# STM32L011K4U7 register map
File version: 1.0
Registers are 32-bit, access not given, reset 0x0 unless marked. A register's access mark holds for its fields unless they carry their own. Offsets are from the block's base; [hi:lo] are bit positions; {n}, {i} and the like mark numbered series.

## IWDG
Base 0x40003000
0x00 KR
  [15:0] KEY
0x04 PR
  [2:0] PR
0x08 RLR
  [11:0] RL
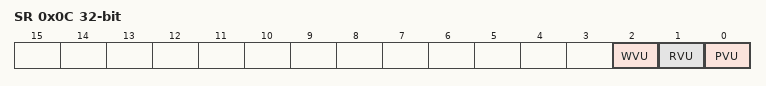
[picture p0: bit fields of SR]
0x0C SR
  [2] WVU, [1] RVU, [0] PVU
0x10 WINR
  [11:0] WIN

## USART2
Base 0x40004400
Same registers: LPUART1 0x40004800
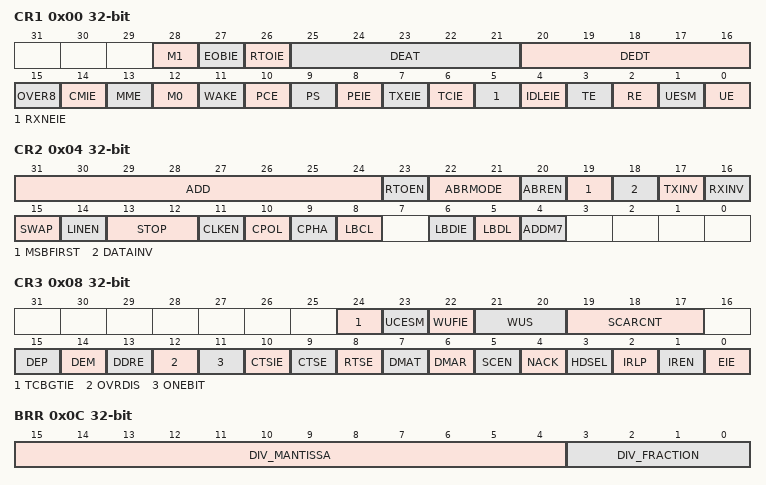
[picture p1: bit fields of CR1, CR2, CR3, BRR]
0x00 CR1
  [28] M1, [27] EOBIE, [26] RTOIE, [25:21] DEAT, [20:16] DEDT, [15] OVER8, [14] CMIE, [13] MME, [12] M0, [11] WAKE, [10] PCE, [9] PS, [8] PEIE, [7] TXEIE, [6] TCIE, [5] RXNEIE, [4] IDLEIE, [3] TE, [2] RE, [1] UESM, [0] UE
0x04 CR2
  [31:24] ADD, [23] RTOEN, [22:21] ABRMODE, [20] ABREN, [19] MSBFIRST, [18] DATAINV, [17] TXINV, [16] RXINV, [15] SWAP, [14] LINEN, [13:12] STOP, [11] CLKEN, [10] CPOL, [9] CPHA, [8] LBCL, [6] LBDIE, [5] LBDL, [4] ADDM7
0x08 CR3
  [24] TCBGTIE, [23] UCESM, [22] WUFIE, [21:20] WUS, [19:17] SCARCNT, [15] DEP, [14] DEM, [13] DDRE, [12] OVRDIS, [11] ONEBIT, [10] CTSIE, [9] CTSE, [8] RTSE, [7] DMAT, [6] DMAR, [5] SCEN, [4] NACK, [3] HDSEL, [2] IRLP, [1] IREN, [0] EIE
0x0C BRR
  [15:4] DIV_MANTISSA, [3:0] DIV_FRACTION
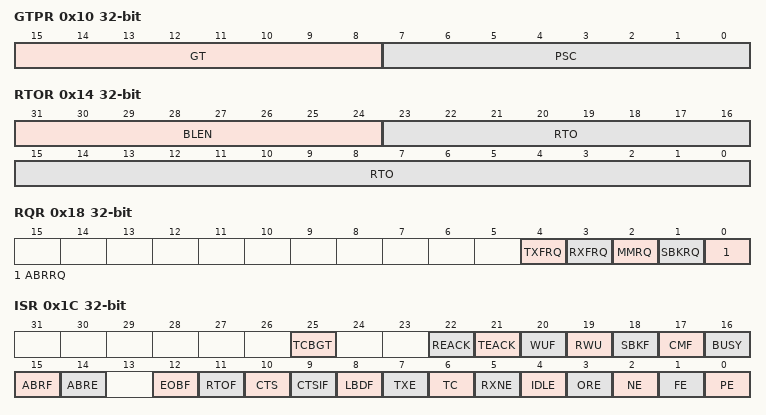
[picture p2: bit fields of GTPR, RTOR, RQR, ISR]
0x10 GTPR
  [15:8] GT, [7:0] PSC
0x14 RTOR
  [31:24] BLEN, [23:0] RTO
0x18 RQR
  [4] TXFRQ, [3] RXFRQ, [2] MMRQ, [1] SBKRQ, [0] ABRRQ
0x1C ISR
  [25] TCBGT, [22] REACK, [21] TEACK, [20] WUF, [19] RWU, [18] SBKF, [17] CMF, [16] BUSY, [15] ABRF, [14] ABRE, [12] EOBF, [11] RTOF, [10] CTS, [9] CTSIF, [8] LBDF, [7] TXE, [6] TC, [5] RXNE, [4] IDLE, [3] ORE, [2] NE, [1] FE, [0] PE
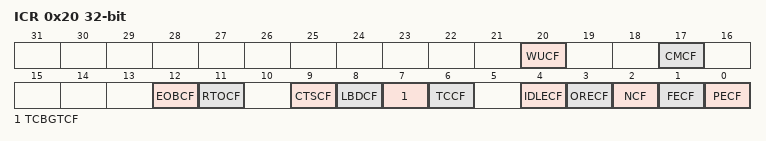
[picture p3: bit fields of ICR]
0x20 ICR
  [20] WUCF, [17] CMCF, [12] EOBCF, [11] RTOCF, [9] CTSCF, [8] LBDCF, [7] TCBGTCF, [6] TCCF, [4] IDLECF, [3] ORECF, [2] NCF, [1] FECF, [0] PECF
0x24 RDR
  [8:0] RDR
0x28 TDR
  [8:0] TDR

## I2C1
Base 0x40005400
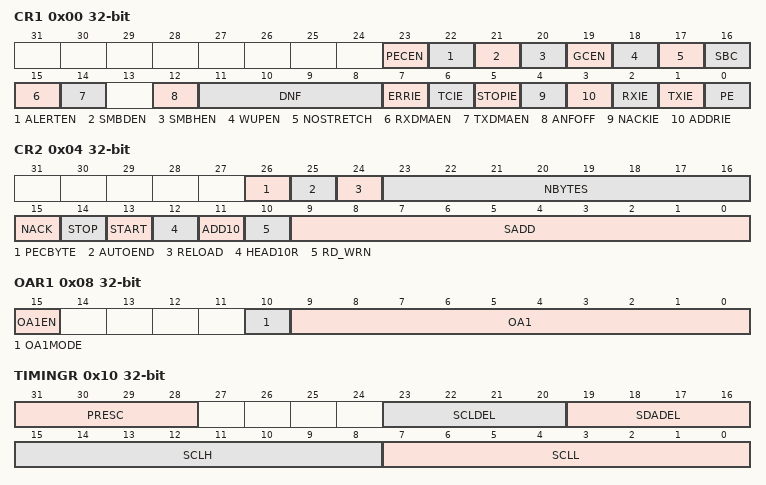
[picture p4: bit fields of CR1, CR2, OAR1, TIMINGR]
0x00 CR1
  [23] PECEN, [22] ALERTEN, [21] SMBDEN, [20] SMBHEN, [19] GCEN, [18] WUPEN, [17] NOSTRETCH, [16] SBC, [15] RXDMAEN, [14] TXDMAEN, [12] ANFOFF, [11:8] DNF, [7] ERRIE, [6] TCIE, [5] STOPIE, [4] NACKIE, [3] ADDRIE, [2] RXIE, [1] TXIE, [0] PE
0x04 CR2
  [26] PECBYTE, [25] AUTOEND, [24] RELOAD, [23:16] NBYTES, [15] NACK, [14] STOP, [13] START, [12] HEAD10R, [11] ADD10, [10] RD_WRN, [9:0] SADD
0x08 OAR1
  [15] OA1EN, [10] OA1MODE, [9:0] OA1
0x0C OAR2
  [15] OA2EN, [10] OA2MASK04, [10:9] OA2MASK06, [10:8] OA2MSK, [7:1] OA2
0x10 TIMINGR
  [31:28] PRESC, [23:20] SCLDEL, [19:16] SDADEL, [15:8] SCLH, [7:0] SCLL
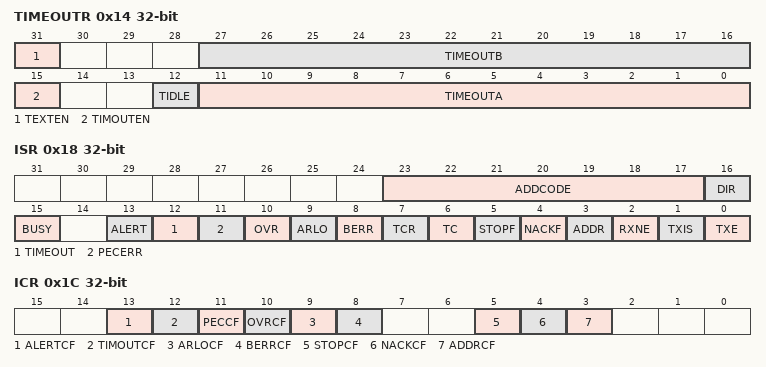
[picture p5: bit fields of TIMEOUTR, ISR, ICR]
0x14 TIMEOUTR
  [31] TEXTEN, [27:16] TIMEOUTB, [15] TIMOUTEN, [12] TIDLE, [11:0] TIMEOUTA
0x18 ISR
  [23:17] ADDCODE, [16] DIR, [15] BUSY, [13] ALERT, [12] TIMEOUT, [11] PECERR, [10] OVR, [9] ARLO, [8] BERR, [7] TCR, [6] TC, [5] STOPF, [4] NACKF, [3] ADDR, [2] RXNE, [1] TXIS, [0] TXE
0x1C ICR
  [13] ALERTCF, [12] TIMOUTCF, [11] PECCF, [10] OVRCF, [9] ARLOCF, [8] BERRCF, [5] STOPCF, [4] NACKCF, [3] ADDRCF
0x20 PECR
  [7:0] PEC
0x24 RXDR
  [7:0] RXDATA
0x28 TXDR
  [7:0] TXDATA

## PWR
Base 0x40007000
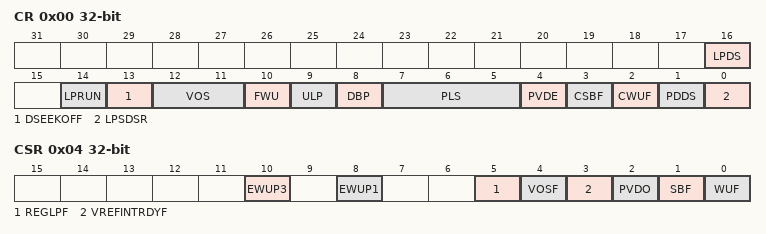
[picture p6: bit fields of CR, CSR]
0x00 CR
  [16] LPDS, [14] LPRUN, [13] DSEEKOFF, [12:11] VOS, [10] FWU, [9] ULP, [8] DBP, [7:5] PLS, [4] PVDE, [3] CSBF, [2] CWUF, [1] PDDS, [0] LPSDSR
0x04 CSR
  [10] EWUP3, [8] EWUP1, [5] REGLPF, [4] VOSF, [3] VREFINTRDYF, [2] PVDO, [1] SBF, [0] WUF

## LPTIM1
Base 0x40007C00
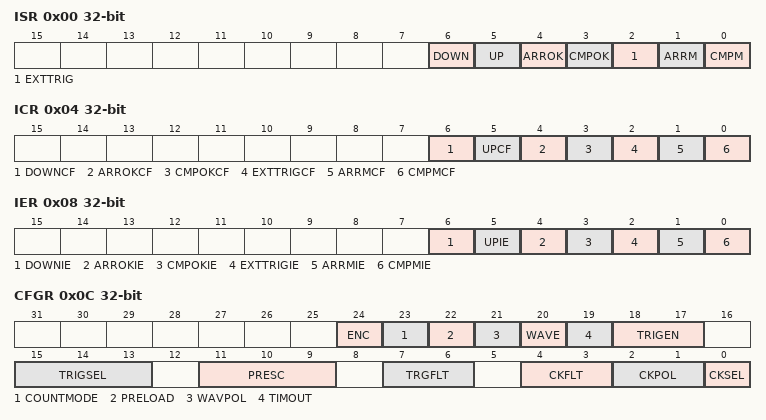
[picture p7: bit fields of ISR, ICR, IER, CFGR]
0x00 ISR
  [6] DOWN, [5] UP, [4] ARROK, [3] CMPOK, [2] EXTTRIG, [1] ARRM, [0] CMPM
0x04 ICR
  [6] DOWNCF, [5] UPCF, [4] ARROKCF, [3] CMPOKCF, [2] EXTTRIGCF, [1] ARRMCF, [0] CMPMCF
0x08 IER
  [6] DOWNIE, [5] UPIE, [4] ARROKIE, [3] CMPOKIE, [2] EXTTRIGIE, [1] ARRMIE, [0] CMPMIE
0x0C CFGR
  [24] ENC, [23] COUNTMODE, [22] PRELOAD, [21] WAVPOL, [20] WAVE, [19] TIMOUT, [18:17] TRIGEN, [15:13] TRIGSEL, [11:9] PRESC, [7:6] TRGFLT, [4:3] CKFLT, [2:1] CKPOL, [0] CKSEL
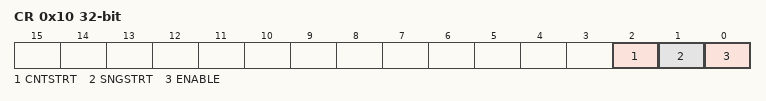
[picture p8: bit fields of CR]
0x10 CR
  [2] CNTSTRT, [1] SNGSTRT, [0] ENABLE
0x14 CMP
  [15:0] CMP
0x18 ARR
  [15:0] ARR
0x1C CNT
  [15:0] CNT

## SYSCFG
Base 0x40010000
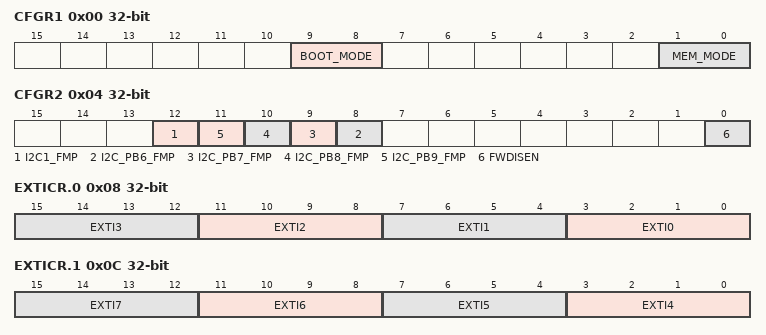
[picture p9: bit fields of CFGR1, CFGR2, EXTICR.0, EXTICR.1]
0x00 CFGR1
  [9:8] BOOT_MODE, [1:0] MEM_MODE
0x04 CFGR2
  [12] I2C1_FMP, [n+2] I2C_PB{n}_FMP (n=6..9), [0] FWDISEN
0x08 EXTICR.0
  [4n+3:4n] EXTI{n} (n=0..3)
0x0C EXTICR.1
  [4n-13:4n-16] EXTI{n} (n=4..7)
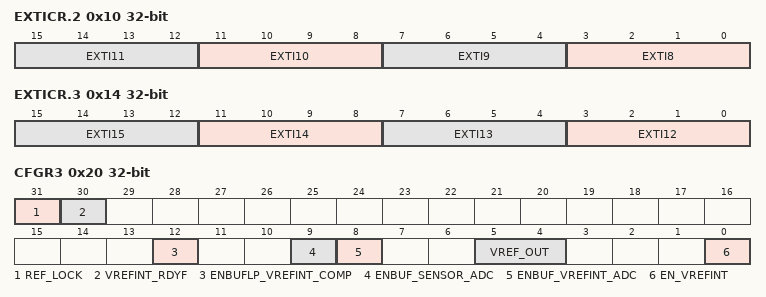
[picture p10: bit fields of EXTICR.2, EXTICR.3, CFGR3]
0x10 EXTICR.2
  [4n-29:4n-32] EXTI{n} (n=8..11)
0x14 EXTICR.3
  [4n-45:4n-48] EXTI{n} (n=12..15)
0x20 CFGR3
  [31] REF_LOCK, [30] VREFINT_RDYF, [12] ENBUFLP_VREFINT_COMP, [9] ENBUF_SENSOR_ADC, [8] ENBUF_VREFINT_ADC, [5:4] VREF_OUT, [0] EN_VREFINT
